# TC35678 register map
Vendor: Toshiba Electronic Devices and Storage Corporation; File version: 0.1
CPU: CM0 r0p0, little endian, no MPU, no FPU, 4 interrupt priority bits
Registers are 32-bit, read-write, no defined reset value unless marked. A register's access mark holds for its fields unless they carry their own. Offsets are from the block's base; [hi:lo] are bit positions; {n}, {i} and the like mark numbered series.

## BluetoothCounter
Base 0x40040240
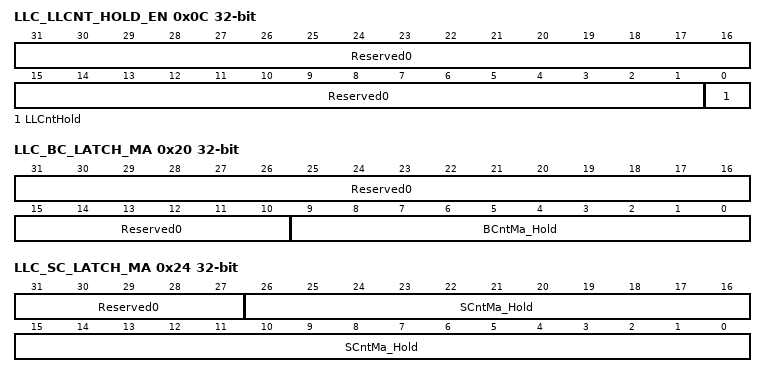
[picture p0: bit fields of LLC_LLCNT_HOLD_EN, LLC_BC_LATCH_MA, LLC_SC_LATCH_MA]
0x0C LLC_LLCNT_HOLD_EN — Hold Bluetooth counter
  [31:1] Reserved0 — Do not change the values.
  [0] LLCntHold — When 0 (or arbitrary value) is set this register, the following registers will hold the values: LLC_BC_LATCH_MA:Master Bit Counter LLC_SC_LATCH_MA:Master Slot Counter Before accessing LLC_BC_LATCH_MA or LLC_SC_LATCH_MA, please set 0 (or arbitrary value) to this register.
0x20 LLC_BC_LATCH_MA ro — Holding Master Bit Counter
  [31:10] Reserved0 — Do not change the values.
  [9:0] BCntMa_Hold rw — Master bit counter value. "Master slot counter" counts up every 1 micro seconds. When this value is 624, this value becomes 0 and SCntMa_Hold value counts up on next count up timing. Before reading this value, please set 0 (or arbitrary value) to LLCntHold.
0x24 LLC_SC_LATCH_MA — Holding Master Slot Counter
  [31:27] Reserved0 — Do not change the values.
  [26:0] SCntMa_Hold — Master slot counter value. "Master slot counter" counts up every 1 slot (625 micro seconds). Before reading this value, please set 0 (or arbitrary value) to LLCntHold.

## PowerManagement — Power Management (GPIO, RTC)
Base 0x40055000
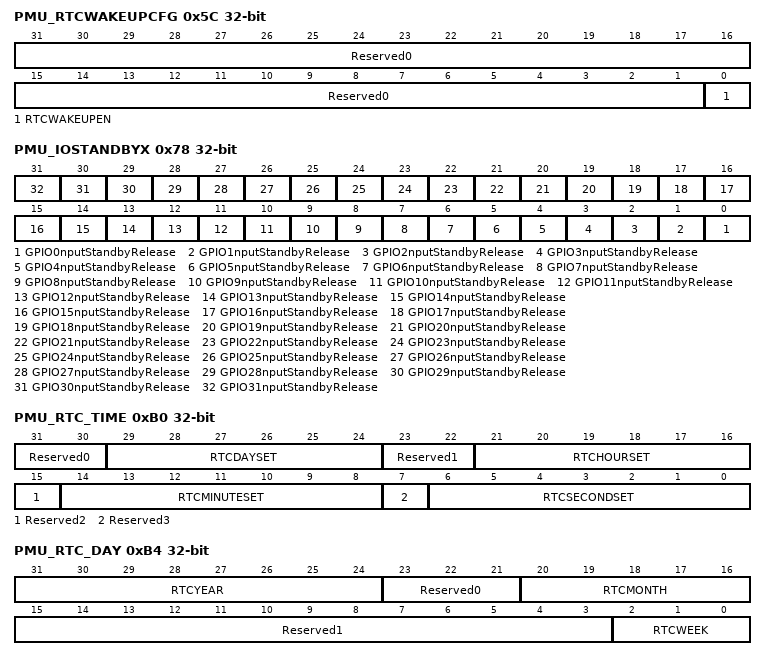
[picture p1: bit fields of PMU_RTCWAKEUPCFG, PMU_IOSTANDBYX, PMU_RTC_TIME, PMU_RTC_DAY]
0x5C PMU_RTCWAKEUPCFG — RTC wakeup config register
  [31:1] Reserved0 — Do not change the values.
  [0] RTCWAKEUPEN — RTC wakeup config 1: Enable wakeup by RTC 0: Disable wakeup by RTC
0x78 PMU_IOSTANDBYX — GPIO input standby
  [n] GPIO{n}nputStandbyRelease (n=0..31) — Input standby release on GPIO{n} 1: Release standby 0: Standby
0xB0 PMU_RTC_TIME — RTC time register
  [31:30] Reserved0 — Do not change the values.
  [29:24] RTCDAYSET — RTC time config of "day" (Binary Coded Decimal) Min: 1 Max: 31
  [23:22] Reserved1 — Do not change the values.
  [21:16] RTCHOURSET — RTC time config of "hour" (Binary Coded Decimal) Min: 0 Max: 23
  [15] Reserved2 — Do not change the values.
  [14:8] RTCMINUTESET — RTC time config of "minute" (Binary Coded Decimal) Min: 0 Max: 59
  [7] Reserved3 — Do not change the values.
  [6:0] RTCSECONDSET — RTC time config of "second" (Binary Coded Decimal) Min: 0 Max: 59
0xB4 PMU_RTC_DAY — RTC date register
  [31:24] RTCYEAR — RTC date config of "year"(Binary Coded Decimal)
  [23:21] Reserved0 — Do not change the values.
  [20:16] RTCMONTH — RTC date config of "month"(Binary Coded Decimal)
  [15:3] Reserved1 — Do not change the values.
  [2:0] RTCWEEK — RTC date config of "week"(Binary Coded Decimal)
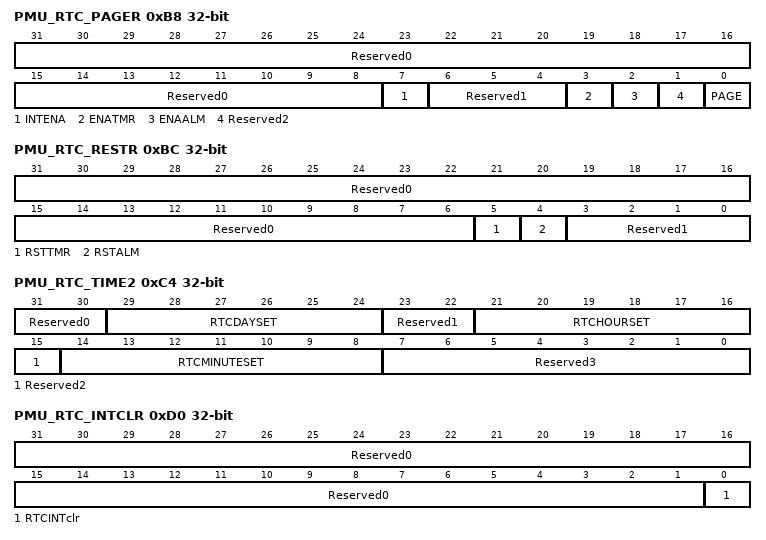
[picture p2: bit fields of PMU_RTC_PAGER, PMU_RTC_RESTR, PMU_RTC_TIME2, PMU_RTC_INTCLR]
0xB8 PMU_RTC_PAGER — RTC control config register
  [31:8] Reserved0 — Do not change the values.
  [7] INTENA — Set interrupt config 0: Disabel 1: Enable
  [6:4] Reserved1 — Always set 0.
  [3] ENATMR — Set clock config 0: Disable 1: Enable
  [2] ENAALM — Set alarm config 0: Disable 1: Enable
  [1] Reserved2 — Do not change the values.
  [0] PAGE — Set Page config 0: Choose Page0 1: Choose Page1
0xBC PMU_RTC_RESTR — RTC reset register
  [31:6] Reserved0 — Always set 0b0000_0000_1100_0001_0000_0000_11
  [5] RSTTMR — Reset clock 0: Not reset 1: Reset If you wan to reset a clock, please set 1 to this value and wait to become 0.
  [4] RSTALM — Reset alarm 0: Not reset 1: Reset If you wan to reset an alarm, please set 1 to this value and wait to become 0.
  [3:0] Reserved1 — Do not change the values.
0xC4 PMU_RTC_TIME2 — RTC time register2
  [31:30] Reserved0 — Do not change the values.
  [29:24] RTCDAYSET — RTC time config of "day" (Binary Coded Decimal) Min: 1 Max: 31
  [23:22] Reserved1 — Do not change the values.
  [21:16] RTCHOURSET — RTC time config of "hour" (Binary Coded Decimal) Min: 0 Max: 23
  [15] Reserved2 — Do not change the values.
  [14:8] RTCMINUTESET — RTC time config of "minute" (Binary Coded Decimal) Min: 0 Max: 59
  [7:0] Reserved3 — Do not change the values.
0xD0 PMU_RTC_INTCLR — RTC interrupt clear register
  [31:1] Reserved0 — Do not change the values.
  [0] RTCINTclr — Clear RTC interrupt 1: Clear 0: Don't care
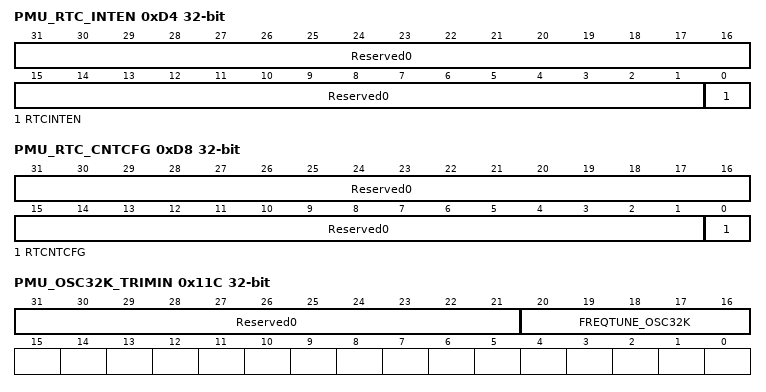
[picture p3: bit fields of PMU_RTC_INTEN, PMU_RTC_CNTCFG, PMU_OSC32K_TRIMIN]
0xD4 PMU_RTC_INTEN — RTC interrupt enable register
  [31:1] Reserved0 — Do not change the values.
  [0] RTCINTEN — Enable RTC interrupt 1: Enable interrupt request 0: Disable interrupt request
0xD8 PMU_RTC_CNTCFG — RTC count cnofig register
  [31:1] Reserved0 — Do not change the values.
  [0] RTCNTCFG — Set RTC config 1: Enable RTC config 0: Disable RTC config
0xE8 PMU_DD_DVSSEL — DCDC DVS control register
  [31:0] val — When you do an ADC of VDDCORE2, set 1 to bit[1] and bit[5]. Do not change the values other than bit[1] and bit[5].
0x118 PMU_XOSC_TRIMIN — XOSC trimming register
  [10:4] XO_FREQ_TUNE — Frequency tune value.
0x11C PMU_OSC32K_TRIMIN — OSC32K trimming register
  [31:21] Reserved0 — Do not change the values.
  [20:16] FREQTUNE_OSC32K — Freqency tune value.
